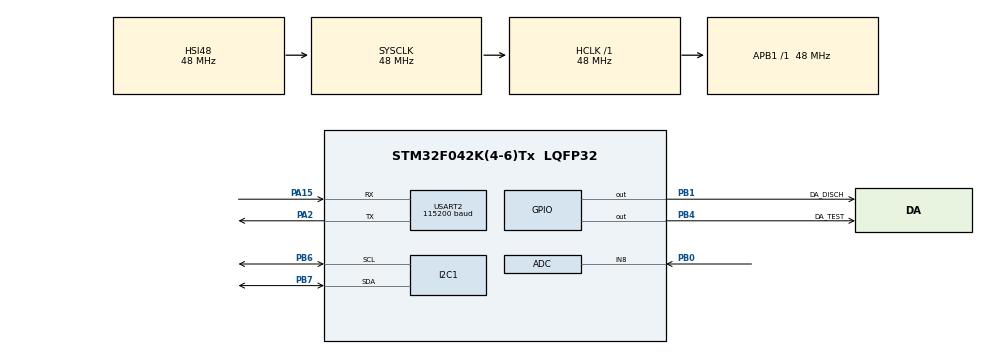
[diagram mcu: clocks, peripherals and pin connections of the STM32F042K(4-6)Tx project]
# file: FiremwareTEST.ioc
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Mcu.Family=STM32F0
Mcu.Name=STM32F042K(4-6)Tx
Mcu.Package=LQFP32
NVIC.TIM14_IRQn=true\:0\:0\:false\:false\:true\:true\:true\:true
NVIC.USART2_IRQn=true\:0\:0\:false\:false\:true\:true\:true\:true
PA15.Mode=Asynchronous
PA15.Signal=USART2_RX
PA2.Mode=Asynchronous
PA2.Signal=USART2_TX
PB0.Mode=IN8
PB0.Signal=ADC_IN8
PB1.GPIO_Label=DA_DISCH
PB1.Signal=GPIO_Output
PB4.GPIO_Label=DA_TEST
PB4.Signal=GPIO_Output
PB6.GPIO_Pu=GPIO_PULLUP
PB6.Mode=I2C
PB6.Signal=I2C1_SCL
PB7.GPIO_Pu=GPIO_PULLUP
PB7.Mode=I2C
PB7.Signal=I2C1_SDA
ProjectManager.HeapSize=0x200
ProjectManager.StackSize=0x400
ProjectManager.TargetToolchain=STM32CubeIDE
RCC.AHBFreq_Value=48000000
RCC.APB1Freq_Value=48000000
RCC.APB1TimFreq_Value=48000000
RCC.HCLKFreq_Value=48000000
RCC.SYSCLKFreq_VALUE=48000000
RCC.SYSCLKSource=RCC_SYSCLKSOURCE_HSI48
TIM14.Period=10
TIM14.Prescaler=47
USART2.BaudRate=115200
USART2.VirtualMode-Asynchronous=VM_ASYNC
VP_TIM14_VS_ClockSourceINT.Mode=Enable_Timer
board=custom

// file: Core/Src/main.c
/* USER CODE BEGIN Header */
/**
  ******************************************************************************
  * @file           : main.c
  * @brief          : Main program body
  ******************************************************************************
  * @attention
  *
  * Copyright (c) 2022 STMicroelectronics.
  * All rights reserved.
  *
  * This software is licensed under terms that can be found in the LICENSE file
  * in the root directory of this software component.
  * If no LICENSE file comes with this software, it is provided AS-IS.
  *
  ******************************************************************************
  */
/* USER CODE END Header */
#include "main.h"

/* USER CODE BEGIN Includes */
#include "string.h"
#include "DS1086.h"
#include "inttypes.h"
/* USER CODE END Includes */

ADC_HandleTypeDef hadc;

I2C_HandleTypeDef hi2c1;

TIM_HandleTypeDef htim14;

UART_HandleTypeDef huart2;

/* USER CODE BEGIN PV */
uint8_t Data[10]=" " ;
uint8_t ligne1[]="---------Welcome---------\n\r" ;
uint8_t valeur[]="      " ;
uint32_t ValeurADC=0;
uint32_t freq=0 ;
/* USER CODE END PV */

void SystemClock_Config(void);
static void MX_GPIO_Init(void);
static void MX_USART2_UART_Init(void);
static void MX_ADC_Init(void);
static void MX_I2C1_Init(void);
static void MX_TIM14_Init(void);

int main(void)
{

  /* MCU Configuration--------------------------------------------------------*/

  /* Reset of all peripherals, Initializes the Flash interface and the Systick. */
  HAL_Init();

  /* Configure the system clock */
  SystemClock_Config();

  /* Initialize all configured peripherals */
  MX_GPIO_Init();
  MX_USART2_UART_Init();
  MX_ADC_Init();
  MX_I2C1_Init();
  MX_TIM14_Init();
  /* USER CODE BEGIN 2 */
  HAL_UART_Transmit_IT(&huart2,ligne1 ,strlen((char*)ligne1));
  HAL_Delay(1000);
  //Scan_I2C();
  HAL_GPIO_WritePin(GPIOB, DA_TEST_Pin, GPIO_PIN_SET);
  ConfigDS1086 (1100) ;

  /* USER CODE END 2 */

  /* Infinite loop */
  while (1)
  {

    /* USER CODE BEGIN 3 */

	  commendHandler ();

  }
  /* USER CODE END 3 */
}

void SystemClock_Config(void)
{
  RCC_OscInitTypeDef RCC_OscInitStruct = {0};
  RCC_ClkInitTypeDef RCC_ClkInitStruct = {0};
  RCC_PeriphCLKInitTypeDef PeriphClkInit = {0};

  /** Initializes the RCC Oscillators according to the specified parameters
  * in the RCC_OscInitTypeDef structure.
  */
  RCC_OscInitStruct.OscillatorType = RCC_OSCILLATORTYPE_HSI|RCC_OSCILLATORTYPE_HSI14
                              |RCC_OSCILLATORTYPE_HSI48;
  RCC_OscInitStruct.HSIState = RCC_HSI_ON;
  RCC_OscInitStruct.HSI48State = RCC_HSI48_ON;
  RCC_OscInitStruct.HSI14State = RCC_HSI14_ON;
  RCC_OscInitStruct.HSICalibrationValue = RCC_HSICALIBRATION_DEFAULT;
  RCC_OscInitStruct.HSI14CalibrationValue = 16;
  RCC_OscInitStruct.PLL.PLLState = RCC_PLL_NONE;
  if (HAL_RCC_OscConfig(&RCC_OscInitStruct) != HAL_OK)
  {
    Error_Handler();
  }

  /** Initializes the CPU, AHB and APB buses clocks
  */
  RCC_ClkInitStruct.ClockType = RCC_CLOCKTYPE_HCLK|RCC_CLOCKTYPE_SYSCLK
                              |RCC_CLOCKTYPE_PCLK1;
  RCC_ClkInitStruct.SYSCLKSource = RCC_SYSCLKSOURCE_HSI48;
  RCC_ClkInitStruct.AHBCLKDivider = RCC_SYSCLK_DIV1;
  RCC_ClkInitStruct.APB1CLKDivider = RCC_HCLK_DIV1;

  if (HAL_RCC_ClockConfig(&RCC_ClkInitStruct, FLASH_LATENCY_1) != HAL_OK)
  {
    Error_Handler();
  }
  PeriphClkInit.PeriphClockSelection = RCC_PERIPHCLK_I2C1;
  PeriphClkInit.I2c1ClockSelection = RCC_I2C1CLKSOURCE_HSI;
  if (HAL_RCCEx_PeriphCLKConfig(&PeriphClkInit) != HAL_OK)
  {
    Error_Handler();
  }
}

static void MX_ADC_Init(void)
{

  ADC_ChannelConfTypeDef sConfig = {0};

  /** Configure the global features of the ADC (Clock, Resolution, Data Alignment and number of conversion)
  */
  hadc.Instance = ADC1;
  hadc.Init.ClockPrescaler = ADC_CLOCK_ASYNC_DIV1;
  hadc.Init.Resolution = ADC_RESOLUTION_12B;
  hadc.Init.DataAlign = ADC_DATAALIGN_RIGHT;
  hadc.Init.ScanConvMode = ADC_SCAN_DIRECTION_FORWARD;
  hadc.Init.EOCSelection = ADC_EOC_SINGLE_CONV;
  hadc.Init.LowPowerAutoWait = DISABLE;
  hadc.Init.LowPowerAutoPowerOff = DISABLE;
  hadc.Init.ContinuousConvMode = DISABLE;
  hadc.Init.DiscontinuousConvMode = DISABLE;
  hadc.Init.ExternalTrigConv = ADC_SOFTWARE_START;
  hadc.Init.ExternalTrigConvEdge = ADC_EXTERNALTRIGCONVEDGE_NONE;
  hadc.Init.DMAContinuousRequests = DISABLE;
  hadc.Init.Overrun = ADC_OVR_DATA_PRESERVED;
  if (HAL_ADC_Init(&hadc) != HAL_OK)
  {
    Error_Handler();
  }

  /** Configure for the selected ADC regular channel to be converted.
  */
  sConfig.Channel = ADC_CHANNEL_8;
  sConfig.Rank = ADC_RANK_CHANNEL_NUMBER;
  sConfig.SamplingTime = ADC_SAMPLETIME_1CYCLE_5;
  if (HAL_ADC_ConfigChannel(&hadc, &sConfig) != HAL_OK)
  {
    Error_Handler();
  }

}

static void MX_I2C1_Init(void)
{

  hi2c1.Instance = I2C1;
  hi2c1.Init.Timing = 0x2000090E;
  hi2c1.Init.OwnAddress1 = 0;
  hi2c1.Init.AddressingMode = I2C_ADDRESSINGMODE_7BIT;
  hi2c1.Init.DualAddressMode = I2C_DUALADDRESS_DISABLE;
  hi2c1.Init.OwnAddress2 = 0;
  hi2c1.Init.OwnAddress2Masks = I2C_OA2_NOMASK;
  hi2c1.Init.GeneralCallMode = I2C_GENERALCALL_DISABLE;
  hi2c1.Init.NoStretchMode = I2C_NOSTRETCH_DISABLE;
  if (HAL_I2C_Init(&hi2c1) != HAL_OK)
  {
    Error_Handler();
  }

  /** Configure Analogue filter
  */
  if (HAL_I2CEx_ConfigAnalogFilter(&hi2c1, I2C_ANALOGFILTER_ENABLE) != HAL_OK)
  {
    Error_Handler();
  }

  /** Configure Digital filter
  */
  if (HAL_I2CEx_ConfigDigitalFilter(&hi2c1, 0) != HAL_OK)
  {
    Error_Handler();
  }

}

static void MX_TIM14_Init(void)
{

  htim14.Instance = TIM14;
  htim14.Init.Prescaler = 47;
  htim14.Init.CounterMode = TIM_COUNTERMODE_UP;
  htim14.Init.Period = 10;
  htim14.Init.ClockDivision = TIM_CLOCKDIVISION_DIV1;
  htim14.Init.AutoReloadPreload = TIM_AUTORELOAD_PRELOAD_DISABLE;
  if (HAL_TIM_Base_Init(&htim14) != HAL_OK)
  {
    Error_Handler();
  }

}

static void MX_USART2_UART_Init(void)
{

  huart2.Instance = USART2;
  huart2.Init.BaudRate = 115200;
  huart2.Init.WordLength = UART_WORDLENGTH_8B;
  huart2.Init.StopBits = UART_STOPBITS_1;
  huart2.Init.Parity = UART_PARITY_NONE;
  huart2.Init.Mode = UART_MODE_TX_RX;
  huart2.Init.HwFlowCtl = UART_HWCONTROL_NONE;
  huart2.Init.OverSampling = UART_OVERSAMPLING_16;
  huart2.Init.OneBitSampling = UART_ONE_BIT_SAMPLE_DISABLE;
  huart2.AdvancedInit.AdvFeatureInit = UART_ADVFEATURE_NO_INIT;
  if (HAL_UART_Init(&huart2) != HAL_OK)
  {
    Error_Handler();
  }

}

static void MX_GPIO_Init(void)
{
  GPIO_InitTypeDef GPIO_InitStruct = {0};

  /* GPIO Ports Clock Enable */
  __HAL_RCC_GPIOA_CLK_ENABLE();
  __HAL_RCC_GPIOB_CLK_ENABLE();

  /*Configure GPIO pin Output Level */
  HAL_GPIO_WritePin(GPIOB, DA_DISCH_Pin|DA_TEST_Pin, GPIO_PIN_RESET);

  /*Configure GPIO pins : DA_DISCH_Pin DA_TEST_Pin */
  GPIO_InitStruct.Pin = DA_DISCH_Pin|DA_TEST_Pin;
  GPIO_InitStruct.Mode = GPIO_MODE_OUTPUT_PP;
  GPIO_InitStruct.Pull = GPIO_NOPULL;
  GPIO_InitStruct.Speed = GPIO_SPEED_FREQ_LOW;
  HAL_GPIO_Init(GPIOB, &GPIO_InitStruct);

}

void Error_Handler(void)
{
  __disable_irq();
  while (1)
  {
  }
}
